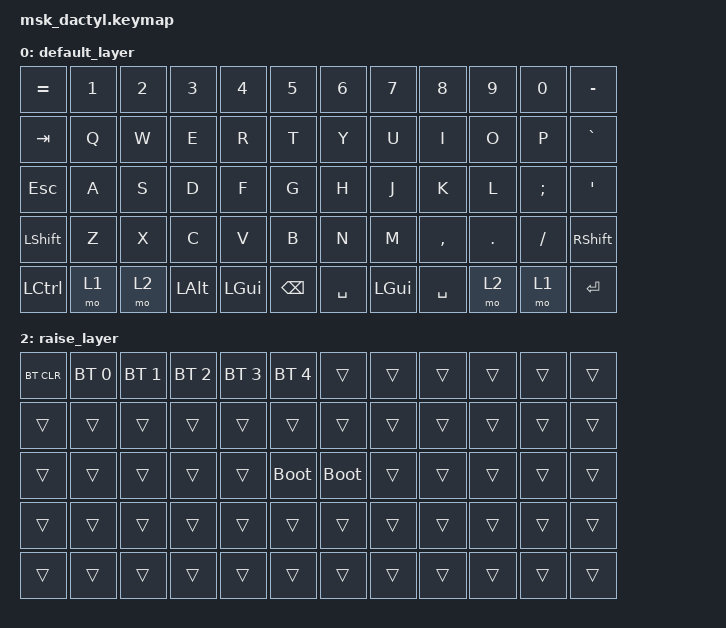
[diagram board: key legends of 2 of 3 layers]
/*
 * Copyright (c) 2020 The ZMK Contributors
 *
 * SPDX-License-Identifier: MIT
 */

#include <behaviors.dtsi>
#include <dt-bindings/zmk/keys.h>
#include <dt-bindings/zmk/bt.h>
#include <dt-bindings/zmk/ext_power.h>

/ {
    combos {
        compatible = "zmk,combos";
        combo_lbraket {
            timeout-ms = <50>;
            key-positions = <53 18>;
            bindings = <&kp LBKT>;
        };
        combo_rbraket {
            timeout-ms = <50>;
            key-positions = <53 19>;
            bindings = <&kp RBKT>;
        };
    };
    keymap {
        compatible = "zmk,keymap";

        default_layer {
            // ------------------------------------------------------------------------------------------------------------
            // |  ESC  |  1  |  2  |  3   |  4   |  5   |                   |  6   |  7    |  8    |  9   |   0   |   `   |
            // |  TAB  |  Q  |  W  |  E   |  R   |  T   |                   |  Y   |  U    |  I    |  O   |   P   |   -   |
            // |  CTRL |  A  |  S  |  D   |  F   |  G   |                   |  H   |  J    |  K    |  L   |   ;   |   '   |
            // | SHIFT |  Z  |  X  |  C   |  V   |  B   |                   |  N   |  M    |  ,    |  .   |   /   | SHIFT |
          bindings = <
            &kp EQUAL &kp N1 &kp N2   &kp N3   &kp N4   &kp N5         &kp N6    &kp N7   &kp N8    &kp N9    &kp N0   &kp MINUS
            &kp TAB   &kp Q  &kp W    &kp E    &kp R    &kp T          &kp Y     &kp U    &kp I     &kp O     &kp P    &kp GRAVE 
            &kp ESC   &kp A  &kp S    &kp D    &kp F    &kp G          &kp H     &kp J    &kp K     &kp L     &kp SEMI &kp SQT
            &kp LSHFT &kp Z  &kp X    &kp C    &kp V    &kp B          &kp N     &kp M    &kp COMMA &kp DOT   &kp FSLH &kp RSHFT
            &kp LCTRL &mo 1  &mo 2    &kp LALT &kp LGUI &kp BSPC       &kp SPACE &kp LGUI &kp SPACE &mo 2     &mo 1    &kp ENTER 
          >;
        };

        lower_layer {
            // ------------------------------------------------------------------------------------------------------------
            // | BTCLR | BT1 | BT2 |  BT3 |  BT4 |  BT5 |                   |      |       |       |      |       |       |
            // |  F1   |  F2 |  F3 |  F4  |  F5  |  F6  |                   |  F7  |  F8   |  F9   |  F10 |  F11  |  F12  |
            // |   `   |  !  |  @  |  #   |  $   |  %   |                   |  ^   |  &    |  *    |  (   |   )   |   ~   |
          bindings = <
            &kp F1     &kp F2           &kp F3            &kp F4            &kp F5       &kp F6           &kp F7      &kp F8    &kp F9    &kp F10   &kp F11   &kp F12
            &trans     &trans           &trans            &trans            &trans       &kp BSLH         &kp LBKT    &kp RBKT  &trans    &trans    &trans    &trans
            &trans     &trans           &trans            &trans            &trans       &kp QMARK        &kp LEFT    &kp DOWN  &kp UP    &kp RIGHT &trans
            &trans     &trans           &trans            &trans            &trans       &trans           &trans      &trans    &trans    &trans    &trans    &trans
            &trans     &trans           &trans            &trans            &trans       &trans           &trans      &trans    &trans    &trans    &trans    &trans
          >;
        };

        raise_layer {
          bindings = <
            &bt BT_CLR &bt BT_SEL 0     &bt BT_SEL 1      &bt BT_SEL 2      &bt BT_SEL 3 &bt BT_SEL 4     &trans      &trans    &trans    &trans    &trans    &trans 
            &trans     &trans           &trans            &trans            &trans       &trans           &trans      &trans    &trans    &trans    &trans    &trans
            &trans     &trans           &trans            &trans            &trans       &bootloader      &bootloader &trans    &trans    &trans    &trans    &trans
            &trans     &trans           &trans            &trans            &trans       &trans           &trans      &trans    &trans    &trans    &trans    &trans
            &trans     &trans           &trans            &trans            &trans       &trans           &trans      &trans    &trans    &trans    &trans    &trans
          >;
        };
    };
};
